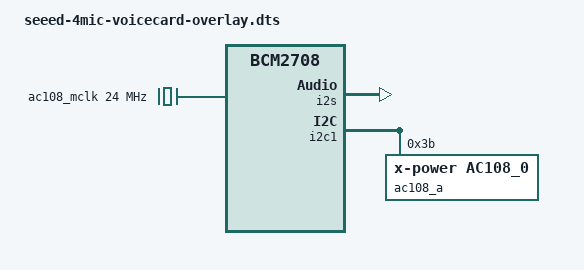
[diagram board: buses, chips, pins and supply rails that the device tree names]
/dts-v1/;
/plugin/;

/ {
	compatible = "brcm,bcm2708";

	fragment@0 {
		target = <&i2s>;
		__overlay__ {
			#sound-dai-cells = <0>;
			status = "okay";
		};
	};

	fragment@1 {
		target-path = "/clocks";
		__overlay__ {
			ac108_mclk: codec-mclk {
				compatible = "fixed-clock";
				#clock-cells = <0>;
				clock-frequency = <24000000>;
			};  
		};
	};

	fragment@2 {
		target = <&i2c1>;
		__overlay__ {
			#address-cells = <1>;
			#size-cells = <0>;
			status = "okay";

			ac108_a: ac108@3b{
				compatible = "x-power,ac108_0";
				reg = <0x3b>;
				#sound-dai-cells = <0>;
				data-protocol = <0>;
			};
		};
	};


	fragment@3 {
		target = <&sound>;

		sound_overlay: __overlay__ {
			compatible = "simple-audio-card";
			simple-audio-card,format = "dsp_a";
			simple-audio-card,name = "seeed-4mic-voicecard"; 
			status = "okay";
		
			simple-audio-card,bitclock-master = <&codec_dai>;
			simple-audio-card,frame-master = <&codec_dai>;
			simple-audio-card,channels-playback-override = <4>;
			simple-audio-card,channels-capture-override  = <4>;

			cpu_dai: simple-audio-card,cpu {
				sound-dai = <&i2s>;
				dai-tdm-slot-num     = <2>;
				dai-tdm-slot-width   = <32>;
				dai-tdm-slot-tx-mask = <1 1 0 0>;
				dai-tdm-slot-rx-mask = <1 1 0 0>;
			};
			codec_dai: simple-audio-card,codec {
				sound-dai = <&ac108_a>;
				clocks =  <&ac108_mclk>;
			};
		};
	};

	__overrides__ {
		card-name = <&sound_overlay>,"seeed-voicecard,name";
	};
};

